//*******************************************************
//  * Name    :CANMatrix_J300_VCU_ACU_20250813.dbc
//  * Author  :MatrixCreat @WangHu
//  * Function:****
//  * Version :V1.0.0
//  * Data    :2025.08.19 20:11:57
//*******************************************************

VERSION "WangHu V1.0"

NS_ :

BS_:

BU_: FSD VCU

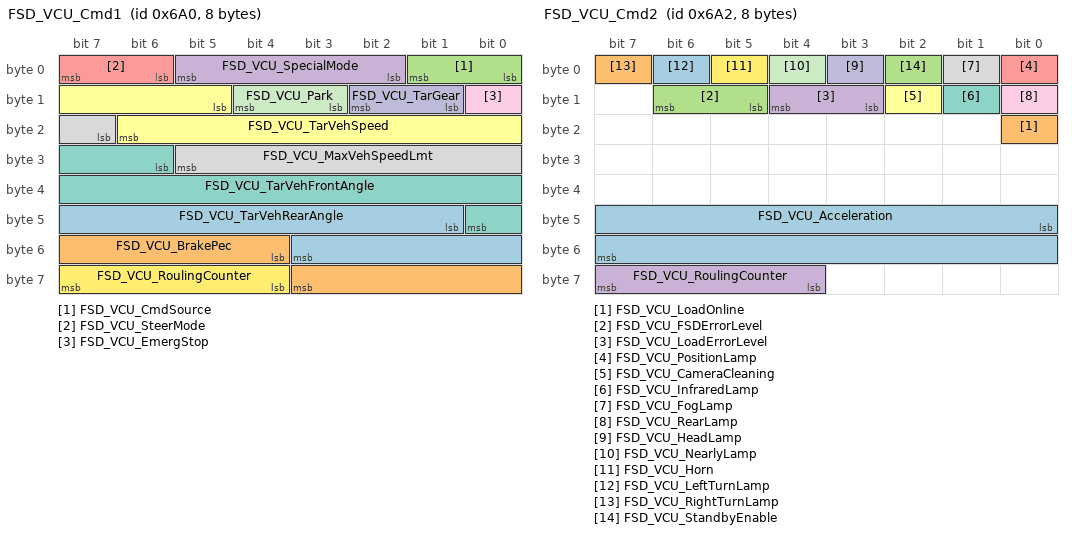
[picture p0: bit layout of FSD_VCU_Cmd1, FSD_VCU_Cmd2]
BO_ 1696 FSD_VCU_Cmd1: 8 FSD
 SG_ FSD_VCU_TarVehRearAngle : 41|11@1+ (1,-800) [-800|1247] "" Vector__XXX
 SG_ FSD_VCU_BrakePec : 52|8@1+ (1,0) [0|100] "" Vector__XXX
 SG_ FSD_VCU_CmdSource : 0|2@1+ (1,0) [0|0] "" Vector__XXX
 SG_ FSD_VCU_SpecialMode : 2|4@1+ (1,0) [0|15] "" Vector__XXX
 SG_ FSD_VCU_SteerMode : 6|2@1+ (1,0) [0|3] "" Vector__XXX
 SG_ FSD_VCU_TarVehSpeed : 13|10@1+ (0.1,0) [0|0] "" Vector__XXX
 SG_ FSD_VCU_TarVehFrontAngle : 30|11@1+ (1,-800) [-800|1247] "" Vector__XXX
 SG_ FSD_VCU_MaxVehSpeedLmt : 23|7@1+ (1,0) [0|127] "" Vector__XXX
 SG_ FSD_VCU_EmergStop : 8|1@1+ (1,0) [0|1] "" Vector__XXX
 SG_ FSD_VCU_TarGear : 9|2@1+ (1,0) [0|3] "" Vector__XXX
 SG_ FSD_VCU_Park : 11|2@1+ (1,0) [0|3] "" Vector__XXX
 SG_ FSD_VCU_RoulingCounter : 60|4@1+ (1,0) [0|15] "" Vector__XXX

BO_ 1698 FSD_VCU_Cmd2: 8 FSD
 SG_ FSD_VCU_Acceleration : 40|16@1+ (0.1,-5) [0|0] "" Vector__XXX
 SG_ FSD_VCU_LoadOnline : 16|1@1+ (1,0) [0|0] "" Vector__XXX
 SG_ FSD_VCU_FSDErrorLevel : 13|2@1+ (1,0) [0|0] "" Vector__XXX
 SG_ FSD_VCU_LoadErrorLevel : 11|2@1+ (1,0) [0|0] "" Vector__XXX
 SG_ FSD_VCU_PositionLamp : 0|1@1+ (1,0) [0|0] "" Vector__XXX
 SG_ FSD_VCU_CameraCleaning : 10|1@1+ (1,0) [0|0] "" Vector__XXX
 SG_ FSD_VCU_InfraredLamp : 9|1@1+ (1,0) [0|0] "" Vector__XXX
 SG_ FSD_VCU_FogLamp : 1|1@1+ (1,0) [0|0] "" Vector__XXX
 SG_ FSD_VCU_RearLamp : 8|1@1+ (1,0) [0|0] "" Vector__XXX
 SG_ FSD_VCU_HeadLamp : 3|1@1+ (1,0) [0|1] "" Vector__XXX
 SG_ FSD_VCU_NearlyLamp : 4|1@1+ (1,0) [0|1] "" Vector__XXX
 SG_ FSD_VCU_Horn : 5|1@1+ (1,0) [0|1] "" Vector__XXX
 SG_ FSD_VCU_LeftTurnLamp : 6|1@1+ (1,0) [0|1] "" Vector__XXX
 SG_ FSD_VCU_RightTurnLamp : 7|1@1+ (1,0) [0|1] "" Vector__XXX
 SG_ FSD_VCU_StandbyEnable : 2|1@1+ (1,0) [0|1] "" Vector__XXX
 SG_ FSD_VCU_RoulingCounter : 60|4@1+ (1,0) [0|15] "" Vector__XXX

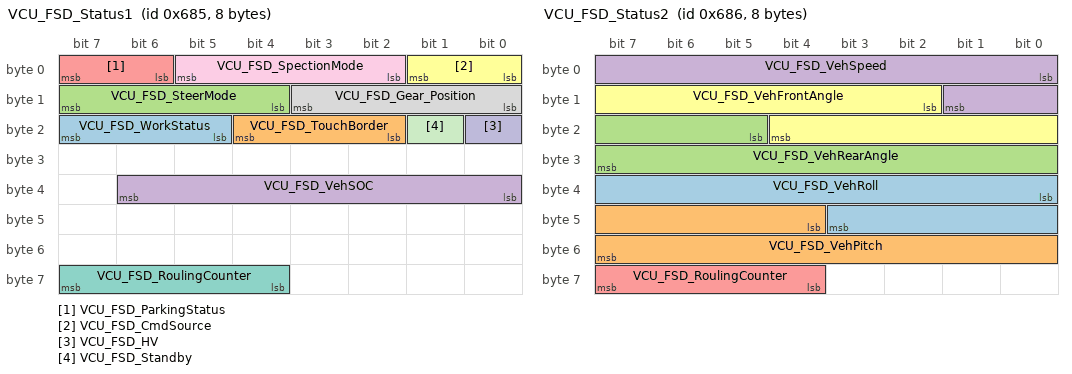
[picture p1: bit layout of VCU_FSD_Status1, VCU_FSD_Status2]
BO_ 1669 VCU_FSD_Status1: 8 VCU
 SG_ VCU_FSD_WorkStatus : 21|3@1+ (1,0) [0|0] "" Vector__XXX
 SG_ VCU_FSD_TouchBorder : 18|3@1+ (1,0) [0|0] "" Vector__XXX
 SG_ VCU_FSD_SteerMode : 12|4@1+ (1,0) [0|0] "" Vector__XXX
 SG_ VCU_FSD_VehSOC : 32|7@1+ (1,0) [0|127] "" Vector__XXX
 SG_ VCU_FSD_ParkingStatus : 6|2@1+ (1,0) [0|2] "" Vector__XXX
 SG_ VCU_FSD_CmdSource : 0|2@1+ (1,0) [0|3] "" Vector__XXX
 SG_ VCU_FSD_RoulingCounter : 60|4@1+ (1,0) [0|15] "" Vector__XXX
 SG_ VCU_FSD_Gear_Position : 8|4@1+ (1,0) [0|6] "" Vector__XXX
 SG_ VCU_FSD_SpectionMode : 2|4@1+ (1,0) [0|15] "" Vector__XXX
 SG_ VCU_FSD_HV : 16|1@1+ (1,0) [0|1] "" Vector__XXX
 SG_ VCU_FSD_Standby : 17|1@1+ (1,0) [0|1] "" Vector__XXX

BO_ 1670 VCU_FSD_Status2: 8 VCU
 SG_ VCU_FSD_VehRoll : 32|12@1+ (0.1,-180) [0|0] "" Vector__XXX
 SG_ VCU_FSD_VehPitch : 44|12@1+ (0.1,-180) [0|0] "" Vector__XXX
 SG_ VCU_FSD_VehRearAngle : 21|11@1+ (1,-800) [-800|1247] "" Vector__XXX
 SG_ VCU_FSD_VehSpeed : 0|10@1+ (0.1,0) [0|102.3] "" Vector__XXX
 SG_ VCU_FSD_RoulingCounter : 60|4@1+ (1,0) [0|15] "" Vector__XXX
 SG_ VCU_FSD_VehFrontAngle : 10|11@1+ (1,-800) [-800|1247] "" Vector__XXX

BO_ 1665 VCU_ErrorMsg1: 8 VCU
 SG_ VCU_DC24ErrorLevel : 34|2@1+ (1,0) [0|3] "" Vector__XXX
 SG_ VCU_LowVoltageBoxErrorLevel : 36|2@1+ (1,0) [0|3] "" Vector__XXX
 SG_ VCU_IMUErrorLevel : 38|2@1+ (1,0) [0|3] "" Vector__XXX
 SG_ VCU_CANbusError : 42|2@1+ (1,0) [0|3] "" Vector__XXX
 SG_ VCU_VehicleErrorLevel : 0|2@1+ (1,0) [0|0] "" Vector__XXX
 SG_ VCU_FrontMotorErrorLevel : 14|2@1+ (1,0) [0|3] "" Vector__XXX
 SG_ VCU_RearMotorErrorLevel : 16|2@1+ (1,0) [0|3] "" Vector__XXX
 SG_ VCU_RightBatteryErrorLevel : 20|2@1+ (1,0) [0|3] "" Vector__XXX
 SG_ VCU_DC12_1200wErrorLevel : 32|2@1+ (1,0) [0|3] "" Vector__XXX
 SG_ VCU_RightPowerErrorLevel : 12|2@1+ (1,0) [0|0] "" Vector__XXX
 SG_ VCU_LeftPowerErrorLevel : 10|2@1+ (1,0) [0|0] "" Vector__XXX
 SG_ VCU_FSDErrorLevel : 8|2@1+ (1,0) [0|0] "" Vector__XXX
 SG_ VCU_FrontAxleErrorLevel : 2|2@1+ (1,0) [0|0] "" Vector__XXX
 SG_ VCU_ChassisControlBoxLevel : 6|2@1+ (1,0) [0|0] "" Vector__XXX
 SG_ VCU_RearAxleErrorLevel : 4|2@1+ (1,0) [0|0] "" Vector__XXX
 SG_ VCU_LeftBatteryLevel : 18|2@1+ (1,0) [0|3] "" Vector__XXX
 SG_ VCU_DC12_600wLevel : 30|2@1+ (1,0) [0|3] "" Vector__XXX
 SG_ VCU_FrontEPSLevel : 26|2@1+ (1,0) [0|3] "" Vector__XXX
 SG_ VCU_RearEPSLevel : 28|2@1+ (1,0) [0|3] "" Vector__XXX
 SG_ VCU_FrontBrakeLevel : 22|2@1+ (1,0) [0|3] "" Vector__XXX
 SG_ VCU_RearBrakeLevel : 24|2@1+ (1,0) [0|3] "" Vector__XXX
 SG_ VCU_LoadErrorLevel : 40|2@1+ (1,0) [0|3] "" Vector__XXX
 SG_ VCU_RemoteErrorLevel : 44|2@1+ (1,0) [0|3] "" Vector__XXX

BO_ 1666 VCU_ErrorMsg2: 8 VCU
 SG_ VCU_DC24Online : 12|1@1+ (1,0) [0|0] "" Vector__XXX
 SG_ VCU_LowVoltageBoxOnline : 14|1@1+ (1,0) [0|0] "" Vector__XXX
 SG_ VCU_IMUOnline : 13|1@1+ (1,0) [0|0] "" Vector__XXX
 SG_ VCU_LoadOnline : 15|1@1+ (1,0) [0|0] "" Vector__XXX
 SG_ VCU_OnlineRoulingCounter : 60|4@1+ (1,0) [0|0] "" Vector__XXX
 SG_ VCU_ErrorCode : 40|16@1+ (1,0) [0|65535] "" Vector__XXX
 SG_ VCU_ShortRangRemote_online : 0|1@1+ (1,0) [0|1] "" Vector__XXX
 SG_ VCU_FrontMotor_online : 6|1@1+ (1,0) [0|1] "" Vector__XXX
 SG_ VCU_FrontEPS_online : 8|1@1+ (1,0) [0|1] "" Vector__XXX
 SG_ VCU_FrontBrake_online : 4|1@1+ (1,0) [0|1] "" Vector__XXX
 SG_ VCU_LeftBattery_online : 2|1@1+ (1,0) [0|1] "" Vector__XXX
 SG_ VCU_DC12_600w_online : 11|1@1+ (1,0) [0|1] "" Vector__XXX
 SG_ VCU_DC12_1200w_online : 10|1@1+ (1,0) [0|1] "" Vector__XXX
 SG_ VCU_RearMotor_online : 7|1@1+ (1,0) [0|1] "" Vector__XXX
 SG_ VCU_RearEPS_online : 9|1@1+ (1,0) [0|1] "" Vector__XXX
 SG_ VCU_RearBrake_online : 5|1@1+ (1,0) [0|1] "" Vector__XXX
 SG_ VCU_RightBattery_online : 3|1@1+ (1,0) [0|1] "" Vector__XXX
 SG_ VCU_FSD_online : 1|1@1+ (1,0) [0|1] "" Vector__XXX

CM_ SG_ 1696 FSD_VCU_TarVehRearAngle "Rear_axle_virtual_steering_wheel_angle";
CM_ SG_ 1696 FSD_VCU_BrakePec "Brake_opening_degree";
CM_ SG_ 1696 FSD_VCU_CmdSource "CmdSource";
CM_ SG_ 1696 FSD_VCU_SpecialMode "Special_Mode";
CM_ SG_ 1696 FSD_VCU_SteerMode "steering_mode";
CM_ SG_ 1696 FSD_VCU_TarVehSpeed "Target_speed";
CM_ SG_ 1696 FSD_VCU_TarVehFrontAngle "Front_axle_virtual_steering_wheel_angle";
CM_ SG_ 1696 FSD_VCU_MaxVehSpeedLmt "Maximum_speed_limit";
CM_ SG_ 1696 FSD_VCU_EmergStop "Emergency_stop";
CM_ SG_ 1696 FSD_VCU_TarGear "Target_gear";
CM_ SG_ 1696 FSD_VCU_Park "parking";
CM_ SG_ 1696 FSD_VCU_RoulingCounter "Life_signals";
CM_ SG_ 1698 FSD_VCU_Acceleration "Reserved_acceleration_control";
CM_ SG_ 1698 FSD_VCU_LoadOnline "Load_online_status";
CM_ SG_ 1698 FSD_VCU_FSDErrorLevel "FSD_fault_level";
CM_ SG_ 1698 FSD_VCU_LoadErrorLevel "Load_fault_level";
CM_ SG_ 1698 FSD_VCU_PositionLamp "position_light";
CM_ SG_ 1698 FSD_VCU_CameraCleaning "Camera_cleaning";
CM_ SG_ 1698 FSD_VCU_InfraredLamp "infrared_lamp";
CM_ SG_ 1698 FSD_VCU_FogLamp "fog_light";
CM_ SG_ 1698 FSD_VCU_RearLamp "reversing_light";
CM_ SG_ 1698 FSD_VCU_HeadLamp "high_beam";
CM_ SG_ 1698 FSD_VCU_NearlyLamp "low_beam";
CM_ SG_ 1698 FSD_VCU_Horn "horn";
CM_ SG_ 1698 FSD_VCU_LeftTurnLamp "Left_Turn_lamp";
CM_ SG_ 1698 FSD_VCU_RightTurnLamp "Right_turn_lamp";
CM_ SG_ 1698 FSD_VCU_StandbyEnable "Standby_Enable";
CM_ SG_ 1698 FSD_VCU_RoulingCounter "Life_signals";
CM_ SG_ 1669 VCU_FSD_WorkStatus "work_status";
CM_ SG_ 1669 VCU_FSD_TouchBorder "Safe_edge_contact_state";
CM_ SG_ 1669 VCU_FSD_SteerMode "steering_mode";
CM_ SG_ 1669 VCU_FSD_VehSOC "Vehicle_power_consumption";
CM_ SG_ 1669 VCU_FSD_ParkingStatus "Parking_brake_status";
CM_ SG_ 1669 VCU_FSD_CmdSource "Current_control_source";
CM_ SG_ 1669 VCU_FSD_RoulingCounter "Life_signals";
CM_ SG_ 1669 VCU_FSD_Gear_Position "gear";
CM_ SG_ 1669 VCU_FSD_SpectionMode "Special_mode_feedback";
CM_ SG_ 1669 VCU_FSD_HV "High_voltage_status_feedback";
CM_ SG_ 1669 VCU_FSD_Standby "Standby_state_feedback";
CM_ SG_ 1670 VCU_FSD_VehRoll "Vehicle_roll_angle";
CM_ SG_ 1670 VCU_FSD_VehPitch "Vehicle_pitch_angle";
CM_ SG_ 1670 VCU_FSD_VehRearAngle "Current_rear_axle_virtual_steering_wheel_angle";
CM_ SG_ 1670 VCU_FSD_VehSpeed "Current_vehicle_speed";
CM_ SG_ 1670 VCU_FSD_RoulingCounter "Life_signals";
CM_ SG_ 1670 VCU_FSD_VehFrontAngle "Current_virtual_steering_wheel_angle_of_front_axle";
CM_ SG_ 1665 VCU_DC24ErrorLevel "DCDC_24V_fault_level";
CM_ SG_ 1665 VCU_LowVoltageBoxErrorLevel "Fault_level_of_low-voltage_distribution_box";
CM_ SG_ 1665 VCU_IMUErrorLevel "IMU_fault_level";
CM_ SG_ 1665 VCU_CANbusError "CAN_bus_fault";
CM_ SG_ 1665 VCU_VehicleErrorLevel "Vehicle_fault_level";
CM_ SG_ 1665 VCU_FrontMotorErrorLevel "Fault_level_of_front_drive_motor";
CM_ SG_ 1665 VCU_RearMotorErrorLevel "Fault_level_of_rear_drive_motor";
CM_ SG_ 1665 VCU_RightBatteryErrorLevel "Right_battery_pack_fault_level";
CM_ SG_ 1665 VCU_DC12_1200wErrorLevel "1200w_DCDC_12V_fault_level";
CM_ SG_ 1665 VCU_RightPowerErrorLevel "Fault_level_of_right_battery_box";
CM_ SG_ 1665 VCU_LeftPowerErrorLevel "Left_battery_box_fault_level";
CM_ SG_ 1665 VCU_FSDErrorLevel "FSD_module_fault_level";
CM_ SG_ 1665 VCU_FrontAxleErrorLevel "Front_axle_fault_level";
CM_ SG_ 1665 VCU_ChassisControlBoxLevel "Fault_level_of_chassis_control_box";
CM_ SG_ 1665 VCU_RearAxleErrorLevel "Rear_axle_fault_level";
CM_ SG_ 1665 VCU_LeftBatteryLevel "Left_battery_pack_fault_level";
CM_ SG_ 1665 VCU_DC12_600wLevel "600W_DCDC_12V_fault_level";
CM_ SG_ 1665 VCU_FrontEPSLevel "Front_EPS_fault_level";
CM_ SG_ 1665 VCU_RearEPSLevel "rear_EPS_fault_level";
CM_ SG_ 1665 VCU_FrontBrakeLevel "Front_brake_fault_level";
CM_ SG_ 1665 VCU_RearBrakeLevel "Rear_brake_fault_level";
CM_ SG_ 1665 VCU_LoadErrorLevel "Load_fault_level";
CM_ SG_ 1665 VCU_RemoteErrorLevel "Remote_control_fault_level";
CM_ SG_ 1666 VCU_DC24Online "DC24V_online_status";
CM_ SG_ 1666 VCU_LowVoltageBoxOnline "Low_voltage_distribution_box_online_status";
CM_ SG_ 1666 VCU_IMUOnline "IMU_online_status";
CM_ SG_ 1666 VCU_LoadOnline "Load_online_status";
CM_ SG_ 1666 VCU_OnlineRoulingCounter "Life_signals";
CM_ SG_ 1666 VCU_ErrorCode "Vehicle_fault_code";
CM_ SG_ 1666 VCU_ShortRangRemote_online "Close_range_remote_control_online_status";
CM_ SG_ 1666 VCU_FrontMotor_online "Front_drive_motor_online_status";
CM_ SG_ 1666 VCU_FrontEPS_online "Front_EPS_online_status";
CM_ SG_ 1666 VCU_FrontBrake_online "Front_brake_online_status";
CM_ SG_ 1666 VCU_LeftBattery_online "Left_battery_pack_online_status";
CM_ SG_ 1666 VCU_DC12_600w_online "600W_DCDC_12V_online_status";
CM_ SG_ 1666 VCU_DC12_1200w_online "1200W_DCDC_12V_online_status";
CM_ SG_ 1666 VCU_RearMotor_online "Rear_drive_motor_online_status";
CM_ SG_ 1666 VCU_RearEPS_online "Rear_EPS_online_status";
CM_ SG_ 1666 VCU_RearBrake_online "Rear_brake_online_status";
CM_ SG_ 1666 VCU_RightBattery_online "Right_battery_pack_online_status";
CM_ SG_ 1666 VCU_FSD_online "FSD_online_status";

BA_DEF_ SG_  "GenSigStartValue" FLOAT 0 1215752192;
BA_DEF_ SG_  "GenSigMaxValue" INT 0 2147483647;
BA_DEF_ SG_  "GenSigSendType" ENUM "FixedPeriodic", "Cyclic";
BA_DEF_ SG_  "GenSigEnvVarType" ENUM  "int","float","undef";
BA_DEF_ BO_  "GenMsgDelayTime" INT 0 0;
BA_DEF_ BO_  "GenMsgNrOfRepetition" INT 0 0;
BA_DEF_ BO_  "GenMsgCycleTime" INT 0 65535;
BA_DEF_ BO_  "GenMsgSendType" ENUM "FixedPeriodic", "Cyclic";
BA_DEF_  "BusType" STRING ;
BA_DEF_  "GenEnvVarPrefix" STRING ;
BA_DEF_  "GenEnvVarEndingSnd" STRING ;
BA_DEF_  "GenEnvVarEndingDsp" STRING ;
BA_DEF_  "DBName" STRING ;
BA_DEF_DEF_  "GenMsgDelayTime" 0;
BA_DEF_DEF_  "GenMsgNrOfRepetition" 0;
BA_DEF_DEF_  "GenSigStartValue" 0;
BA_DEF_DEF_  "GenSigMaxValue" 0;
BA_DEF_DEF_  "GenSigSendType" "FixedPeriodic";
BA_DEF_DEF_  "GenSigEnvVarType" "undef";
BA_DEF_DEF_  "GenMsgCycleTime" 0;
BA_DEF_DEF_  "GenMsgSendType" "FixedPeriodic";
BA_DEF_DEF_  "BusType" "CAN";
BA_DEF_DEF_  "GenEnvVarPrefix" "PE";
BA_DEF_DEF_  "GenEnvVarEndingSnd" "_Ps";
BA_DEF_DEF_  "GenEnvVarEndingDsp" "_Pd";
BA_DEF_DEF_  "DBName" "";

BA_ "DBName" "CanMatrix";
BA_ "GenMsgCycleTime" BO_ 1696 20;
BA_ "GenMsgNrOfRepetition" BO_ 1696 1;
BA_ "GenMsgDelayTime" BO_ 1696 1;
BA_ "GenSigMaxValue" SG_ 1696 FSD_VCU_TarVehRearAngle 4095;
BA_ "GenSigSendType" SG_ 1696 FSD_VCU_TarVehRearAngle 1;
BA_ "GenSigMaxValue" SG_ 1696 FSD_VCU_BrakePec 255;
BA_ "GenSigSendType" SG_ 1696 FSD_VCU_BrakePec 1;
BA_ "GenSigSendType" SG_ 1696 FSD_VCU_CmdSource 1;
BA_ "GenSigMaxValue" SG_ 1696 FSD_VCU_SpecialMode 15;
BA_ "GenSigSendType" SG_ 1696 FSD_VCU_SpecialMode 1;
BA_ "GenSigMaxValue" SG_ 1696 FSD_VCU_SteerMode 15;
BA_ "GenSigSendType" SG_ 1696 FSD_VCU_SteerMode 1;
BA_ "GenSigMaxValue" SG_ 1696 FSD_VCU_TarVehSpeed 4095;
BA_ "GenSigSendType" SG_ 1696 FSD_VCU_TarVehSpeed 1;
BA_ "GenSigMaxValue" SG_ 1696 FSD_VCU_TarVehFrontAngle 4095;
BA_ "GenSigSendType" SG_ 1696 FSD_VCU_TarVehFrontAngle 1;
BA_ "GenSigMaxValue" SG_ 1696 FSD_VCU_MaxVehSpeedLmt 255;
BA_ "GenSigSendType" SG_ 1696 FSD_VCU_MaxVehSpeedLmt 1;
BA_ "GenSigMaxValue" SG_ 1696 FSD_VCU_EmergStop 1;
BA_ "GenSigSendType" SG_ 1696 FSD_VCU_EmergStop 1;
BA_ "GenSigMaxValue" SG_ 1696 FSD_VCU_TarGear 3;
BA_ "GenSigSendType" SG_ 1696 FSD_VCU_TarGear 1;
BA_ "GenSigMaxValue" SG_ 1696 FSD_VCU_Park 3;
BA_ "GenSigSendType" SG_ 1696 FSD_VCU_Park 1;
BA_ "GenSigMaxValue" SG_ 1696 FSD_VCU_RoulingCounter 15;
BA_ "GenSigSendType" SG_ 1696 FSD_VCU_RoulingCounter 1;
BA_ "GenMsgCycleTime" BO_ 1698 100;
BA_ "GenMsgNrOfRepetition" BO_ 1698 1;
BA_ "GenMsgDelayTime" BO_ 1698 1;
BA_ "GenSigStartValue" SG_ 1698 FSD_VCU_Acceleration 50;
BA_ "GenSigSendType" SG_ 1698 FSD_VCU_Acceleration 1;
BA_ "GenSigSendType" SG_ 1698 FSD_VCU_LoadOnline 1;
BA_ "GenSigSendType" SG_ 1698 FSD_VCU_FSDErrorLevel 1;
BA_ "GenSigSendType" SG_ 1698 FSD_VCU_LoadErrorLevel 1;
BA_ "GenSigSendType" SG_ 1698 FSD_VCU_PositionLamp 1;
BA_ "GenSigSendType" SG_ 1698 FSD_VCU_CameraCleaning 1;
BA_ "GenSigSendType" SG_ 1698 FSD_VCU_InfraredLamp 1;
BA_ "GenSigSendType" SG_ 1698 FSD_VCU_FogLamp 1;
BA_ "GenSigSendType" SG_ 1698 FSD_VCU_RearLamp 1;
BA_ "GenSigMaxValue" SG_ 1698 FSD_VCU_HeadLamp 1;
BA_ "GenSigSendType" SG_ 1698 FSD_VCU_HeadLamp 1;
BA_ "GenSigMaxValue" SG_ 1698 FSD_VCU_NearlyLamp 1;
BA_ "GenSigSendType" SG_ 1698 FSD_VCU_NearlyLamp 1;
BA_ "GenSigMaxValue" SG_ 1698 FSD_VCU_Horn 1;
BA_ "GenSigSendType" SG_ 1698 FSD_VCU_Horn 1;
BA_ "GenSigMaxValue" SG_ 1698 FSD_VCU_LeftTurnLamp 1;
BA_ "GenSigSendType" SG_ 1698 FSD_VCU_LeftTurnLamp 1;
BA_ "GenSigMaxValue" SG_ 1698 FSD_VCU_RightTurnLamp 1;
BA_ "GenSigSendType" SG_ 1698 FSD_VCU_RightTurnLamp 1;
BA_ "GenSigMaxValue" SG_ 1698 FSD_VCU_StandbyEnable 1;
BA_ "GenSigSendType" SG_ 1698 FSD_VCU_StandbyEnable 1;
BA_ "GenSigMaxValue" SG_ 1698 FSD_VCU_RoulingCounter 15;
BA_ "GenSigSendType" SG_ 1698 FSD_VCU_RoulingCounter 1;
BA_ "GenMsgCycleTime" BO_ 1669 20;
BA_ "GenMsgNrOfRepetition" BO_ 1669 1;
BA_ "GenMsgDelayTime" BO_ 1669 1;
BA_ "GenSigSendType" SG_ 1669 VCU_FSD_WorkStatus 1;
BA_ "GenSigSendType" SG_ 1669 VCU_FSD_TouchBorder 1;
BA_ "GenSigSendType" SG_ 1669 VCU_FSD_SteerMode 1;
BA_ "GenSigMaxValue" SG_ 1669 VCU_FSD_VehSOC 255;
BA_ "GenSigSendType" SG_ 1669 VCU_FSD_VehSOC 1;
BA_ "GenSigMaxValue" SG_ 1669 VCU_FSD_ParkingStatus 3;
BA_ "GenSigSendType" SG_ 1669 VCU_FSD_ParkingStatus 1;
BA_ "GenSigMaxValue" SG_ 1669 VCU_FSD_CmdSource 1;
BA_ "GenSigSendType" SG_ 1669 VCU_FSD_CmdSource 1;
BA_ "GenSigMaxValue" SG_ 1669 VCU_FSD_RoulingCounter 15;
BA_ "GenSigSendType" SG_ 1669 VCU_FSD_RoulingCounter 1;
BA_ "GenSigMaxValue" SG_ 1669 VCU_FSD_Gear_Position 15;
BA_ "GenSigSendType" SG_ 1669 VCU_FSD_Gear_Position 1;
BA_ "GenSigMaxValue" SG_ 1669 VCU_FSD_SpectionMode 15;
BA_ "GenSigSendType" SG_ 1669 VCU_FSD_SpectionMode 1;
BA_ "GenSigMaxValue" SG_ 1669 VCU_FSD_HV 1;
BA_ "GenSigSendType" SG_ 1669 VCU_FSD_HV 1;
BA_ "GenSigMaxValue" SG_ 1669 VCU_FSD_Standby 1;
BA_ "GenSigSendType" SG_ 1669 VCU_FSD_Standby 1;
BA_ "GenMsgCycleTime" BO_ 1670 20;
BA_ "GenMsgNrOfRepetition" BO_ 1670 1;
BA_ "GenMsgDelayTime" BO_ 1670 1;
BA_ "GenSigStartValue" SG_ 1670 VCU_FSD_VehRoll 1800;
BA_ "GenSigSendType" SG_ 1670 VCU_FSD_VehRoll 1;
BA_ "GenSigStartValue" SG_ 1670 VCU_FSD_VehPitch 1800;
BA_ "GenSigSendType" SG_ 1670 VCU_FSD_VehPitch 1;
BA_ "GenSigSendType" SG_ 1670 VCU_FSD_VehRearAngle 1;
BA_ "GenSigMaxValue" SG_ 1670 VCU_FSD_VehSpeed 4095;
BA_ "GenSigSendType" SG_ 1670 VCU_FSD_VehSpeed 1;
BA_ "GenSigMaxValue" SG_ 1670 VCU_FSD_RoulingCounter 15;
BA_ "GenSigSendType" SG_ 1670 VCU_FSD_RoulingCounter 1;
BA_ "GenSigSendType" SG_ 1670 VCU_FSD_VehFrontAngle 1;
BA_ "GenMsgCycleTime" BO_ 1665 100;
BA_ "GenMsgNrOfRepetition" BO_ 1665 1;
BA_ "GenMsgDelayTime" BO_ 1665 1;
BA_ "GenMsgSendType" BO_ 1665 1;
BA_ "GenSigMaxValue" SG_ 1665 VCU_DC24ErrorLevel 15;
BA_ "GenSigSendType" SG_ 1665 VCU_DC24ErrorLevel 1;
BA_ "GenSigMaxValue" SG_ 1665 VCU_LowVoltageBoxErrorLevel 15;
BA_ "GenSigSendType" SG_ 1665 VCU_LowVoltageBoxErrorLevel 1;
BA_ "GenSigMaxValue" SG_ 1665 VCU_IMUErrorLevel 15;
BA_ "GenSigSendType" SG_ 1665 VCU_IMUErrorLevel 1;
BA_ "GenSigMaxValue" SG_ 1665 VCU_CANbusError 15;
BA_ "GenSigSendType" SG_ 1665 VCU_CANbusError 1;
BA_ "GenSigSendType" SG_ 1665 VCU_VehicleErrorLevel 1;
BA_ "GenSigMaxValue" SG_ 1665 VCU_FrontMotorErrorLevel 15;
BA_ "GenSigSendType" SG_ 1665 VCU_FrontMotorErrorLevel 1;
BA_ "GenSigMaxValue" SG_ 1665 VCU_RearMotorErrorLevel 15;
BA_ "GenSigSendType" SG_ 1665 VCU_RearMotorErrorLevel 1;
BA_ "GenSigMaxValue" SG_ 1665 VCU_RightBatteryErrorLevel 15;
BA_ "GenSigSendType" SG_ 1665 VCU_RightBatteryErrorLevel 1;
BA_ "GenSigMaxValue" SG_ 1665 VCU_DC12_1200wErrorLevel 15;
BA_ "GenSigSendType" SG_ 1665 VCU_DC12_1200wErrorLevel 1;
BA_ "GenSigSendType" SG_ 1665 VCU_RightPowerErrorLevel 1;
BA_ "GenSigSendType" SG_ 1665 VCU_LeftPowerErrorLevel 1;
BA_ "GenSigSendType" SG_ 1665 VCU_FSDErrorLevel 1;
BA_ "GenSigSendType" SG_ 1665 VCU_FrontAxleErrorLevel 1;
BA_ "GenSigSendType" SG_ 1665 VCU_ChassisControlBoxLevel 1;
BA_ "GenSigSendType" SG_ 1665 VCU_RearAxleErrorLevel 1;
BA_ "GenSigMaxValue" SG_ 1665 VCU_LeftBatteryLevel 15;
BA_ "GenSigSendType" SG_ 1665 VCU_LeftBatteryLevel 1;
BA_ "GenSigMaxValue" SG_ 1665 VCU_DC12_600wLevel 15;
BA_ "GenSigSendType" SG_ 1665 VCU_DC12_600wLevel 1;
BA_ "GenSigMaxValue" SG_ 1665 VCU_FrontEPSLevel 15;
BA_ "GenSigSendType" SG_ 1665 VCU_FrontEPSLevel 1;
BA_ "GenSigMaxValue" SG_ 1665 VCU_RearEPSLevel 15;
BA_ "GenSigSendType" SG_ 1665 VCU_RearEPSLevel 1;
BA_ "GenSigMaxValue" SG_ 1665 VCU_FrontBrakeLevel 15;
BA_ "GenSigSendType" SG_ 1665 VCU_FrontBrakeLevel 1;
BA_ "GenSigMaxValue" SG_ 1665 VCU_RearBrakeLevel 15;
BA_ "GenSigSendType" SG_ 1665 VCU_RearBrakeLevel 1;
BA_ "GenSigMaxValue" SG_ 1665 VCU_LoadErrorLevel 15;
BA_ "GenSigSendType" SG_ 1665 VCU_LoadErrorLevel 1;
BA_ "GenSigMaxValue" SG_ 1665 VCU_RemoteErrorLevel 15;
BA_ "GenSigSendType" SG_ 1665 VCU_RemoteErrorLevel 1;
BA_ "GenMsgCycleTime" BO_ 1666 100;
BA_ "GenMsgNrOfRepetition" BO_ 1666 1;
BA_ "GenMsgDelayTime" BO_ 1666 1;
BA_ "GenMsgSendType" BO_ 1666 1;
BA_ "GenSigSendType" SG_ 1666 VCU_DC24Online 1;
BA_ "GenSigSendType" SG_ 1666 VCU_LowVoltageBoxOnline 1;
BA_ "GenSigSendType" SG_ 1666 VCU_IMUOnline 1;
BA_ "GenSigSendType" SG_ 1666 VCU_LoadOnline 1;
BA_ "GenSigSendType" SG_ 1666 VCU_OnlineRoulingCounter 1;
BA_ "GenSigMaxValue" SG_ 1666 VCU_ErrorCode 65535;
BA_ "GenSigSendType" SG_ 1666 VCU_ErrorCode 1;
BA_ "GenSigMaxValue" SG_ 1666 VCU_ShortRangRemote_online 1;
BA_ "GenSigSendType" SG_ 1666 VCU_ShortRangRemote_online 1;
BA_ "GenSigMaxValue" SG_ 1666 VCU_FrontMotor_online 1;
BA_ "GenSigSendType" SG_ 1666 VCU_FrontMotor_online 1;
BA_ "GenSigMaxValue" SG_ 1666 VCU_FrontEPS_online 1;
BA_ "GenSigSendType" SG_ 1666 VCU_FrontEPS_online 1;
BA_ "GenSigMaxValue" SG_ 1666 VCU_FrontBrake_online 1;
BA_ "GenSigSendType" SG_ 1666 VCU_FrontBrake_online 1;
BA_ "GenSigMaxValue" SG_ 1666 VCU_LeftBattery_online 1;
BA_ "GenSigSendType" SG_ 1666 VCU_LeftBattery_online 1;
BA_ "GenSigMaxValue" SG_ 1666 VCU_DC12_600w_online 1;
BA_ "GenSigSendType" SG_ 1666 VCU_DC12_600w_online 1;
BA_ "GenSigMaxValue" SG_ 1666 VCU_DC12_1200w_online 1;
BA_ "GenSigSendType" SG_ 1666 VCU_DC12_1200w_online 1;
BA_ "GenSigMaxValue" SG_ 1666 VCU_RearMotor_online 1;
BA_ "GenSigSendType" SG_ 1666 VCU_RearMotor_online 1;
BA_ "GenSigMaxValue" SG_ 1666 VCU_RearEPS_online 1;
BA_ "GenSigSendType" SG_ 1666 VCU_RearEPS_online 1;
BA_ "GenSigMaxValue" SG_ 1666 VCU_RearBrake_online 1;
BA_ "GenSigSendType" SG_ 1666 VCU_RearBrake_online 1;
BA_ "GenSigMaxValue" SG_ 1666 VCU_RightBattery_online 1;
BA_ "GenSigSendType" SG_ 1666 VCU_RightBattery_online 1;
BA_ "GenSigMaxValue" SG_ 1666 VCU_FSD_online 1;
BA_ "GenSigSendType" SG_ 1666 VCU_FSD_online 1;

VAL_ 1696 FSD_VCU_CmdSource 0 " Not selected " 1 "FSD " 2 " Close range remote control";
VAL_ 1696 FSD_VCU_SpecialMode 0 " Bench mode " 1 " Economic Model " 2 " Standard Mode " 3 " Sand Mode " 4 " Ramp mode " 5 " Mud mode";
VAL_ 1696 FSD_VCU_SteerMode 0 " Front axle steering " 1 " Full bridge steering " 2 " Rear axle steering";
VAL_ 1696 FSD_VCU_EmergStop 0 " No emergency stop " 1 " Emergency stop";
VAL_ 1696 FSD_VCU_TarGear 0 "N" 1 "D" 2 "R";
VAL_ 1696 FSD_VCU_Park 0 " Parking " 1 " Release parking";
VAL_ 1698 FSD_VCU_LoadOnline 0 "offline" 1 "online";
VAL_ 1698 FSD_VCU_FSDErrorLevel 0 "No fault" 1 "Minor fault" 2 "General fault" 3 "Serious fault";
VAL_ 1698 FSD_VCU_LoadErrorLevel 0 "No fault" 1 "Minor fault" 2 "General fault" 3 "Serious fault";
VAL_ 1698 FSD_VCU_PositionLamp 0 "disable" 1 "enable";
VAL_ 1698 FSD_VCU_CameraCleaning 0 "disable" 1 "enable";
VAL_ 1698 FSD_VCU_InfraredLamp 0 "disable" 1 "enable";
VAL_ 1698 FSD_VCU_FogLamp 0 "disable" 1 "enable";
VAL_ 1698 FSD_VCU_RearLamp 0 "disable" 1 "enable";
VAL_ 1698 FSD_VCU_HeadLamp 0 "disable" 1 "enable";
VAL_ 1698 FSD_VCU_NearlyLamp 0 "disable" 1 "enable";
VAL_ 1698 FSD_VCU_Horn 0 "disable" 1 "enable";
VAL_ 1698 FSD_VCU_LeftTurnLamp 0 "disable" 1 "enable";
VAL_ 1698 FSD_VCU_RightTurnLamp 0 "disable" 1 "enable";
VAL_ 1698 FSD_VCU_StandbyEnable 0 "disable" 1 "enable";
VAL_ 1669 VCU_FSD_WorkStatus 0 " Normal operation " 1 " limping " 2 " Fault parking";
VAL_ 1669 VCU_FSD_TouchBorder 0 " No contact " 1 " Contact";
VAL_ 1669 VCU_FSD_SteerMode 0 " Front axle steering " 1 " Full bridge steering " 2 " Rear axle steering";
VAL_ 1669 VCU_FSD_ParkingStatus 0 " Not parked " 1 " Parking";
VAL_ 1669 VCU_FSD_CmdSource 0 " Not selected " 1 "FSD " 2 " Close range remote control";
VAL_ 1669 VCU_FSD_Gear_Position 0 "N" 1 "D" 2 "R";
VAL_ 1669 VCU_FSD_SpectionMode 0 " Bench mode " 1 " Economic Model " 2 " Standard Mode " 3 " Sand Mode " 4 " Ramp mode " 5 " Mud mode";
VAL_ 1669 VCU_FSD_HV 0 " High voltage not applied " 1 " High Voltage";
VAL_ 1669 VCU_FSD_Standby 0 " Standby " 1 " Not in standby mode";
VAL_ 1665 VCU_DC24ErrorLevel 0 "No fault" 1 "Minor fault" 2 "General fault" 3 "Serious fault";
VAL_ 1665 VCU_LowVoltageBoxErrorLevel 0 "No fault" 1 "Minor fault" 2 "General fault" 3 "Serious fault";
VAL_ 1665 VCU_IMUErrorLevel 0 "No fault" 1 "Minor fault" 2 "General fault" 3 "Serious fault";
VAL_ 1665 VCU_CANbusError 0 "FCANBUS fault" 1 "RCANBUS fault" 2 "FRCANBUS fault";
VAL_ 1665 VCU_VehicleErrorLevel 0 "No fault" 1 "Minor fault" 2 "General fault" 3 "Serious fault";
VAL_ 1665 VCU_FrontMotorErrorLevel 0 "No fault" 1 "Minor fault" 2 "General fault" 3 "Serious fault";
VAL_ 1665 VCU_RearMotorErrorLevel 0 "No fault" 1 "Minor fault" 2 "General fault" 3 "Serious fault";
VAL_ 1665 VCU_RightBatteryErrorLevel 0 "No fault" 1 "Minor fault" 2 "General fault" 3 "Serious fault";
VAL_ 1665 VCU_DC12_1200wErrorLevel 0 "No fault" 1 "Minor fault" 2 "General fault" 3 "Serious fault";
VAL_ 1665 VCU_RightPowerErrorLevel 0 "No fault" 1 "Minor fault" 2 "General fault" 3 "Serious fault";
VAL_ 1665 VCU_LeftPowerErrorLevel 0 "No fault" 1 "Minor fault" 2 "General fault" 3 "Serious fault";
VAL_ 1665 VCU_FSDErrorLevel 0 "FCANBUS fault" 1 "RCANBUS fault" 2 "FRCANBUS fault";
VAL_ 1665 VCU_FrontAxleErrorLevel 0 "No fault" 1 "Minor fault" 2 "General fault" 3 "Serious fault";
VAL_ 1665 VCU_ChassisControlBoxLevel 0 "No fault" 1 "Minor fault" 2 "General fault" 3 "Serious fault";
VAL_ 1665 VCU_RearAxleErrorLevel 0 "No fault" 1 "Minor fault" 2 "General fault" 3 "Serious fault";
VAL_ 1665 VCU_LeftBatteryLevel 0 "No fault" 1 "Minor fault" 2 "General fault" 3 "Serious fault";
VAL_ 1665 VCU_DC12_600wLevel 0 "No fault" 1 "Minor fault" 2 "General fault" 3 "Serious fault";
VAL_ 1665 VCU_FrontEPSLevel 0 "No fault" 1 "Minor fault" 2 "General fault" 3 "Serious fault";
VAL_ 1665 VCU_RearEPSLevel 0 "No fault" 1 "Minor fault" 2 "General fault" 3 "Serious fault";
VAL_ 1665 VCU_FrontBrakeLevel 0 "No fault" 1 "Minor fault" 2 "General fault" 3 "Serious fault";
VAL_ 1665 VCU_RearBrakeLevel 0 "No fault" 1 "Minor fault" 2 "General fault" 3 "Serious fault";
VAL_ 1665 VCU_LoadErrorLevel 0 "No fault" 1 "Minor fault" 2 "General fault" 3 "Serious fault";
VAL_ 1665 VCU_RemoteErrorLevel 0 "No fault" 1 "Minor fault" 2 "General fault" 3 "Serious fault";
VAL_ 1666 VCU_DC24Online 0 "offline" 1 "online";
VAL_ 1666 VCU_LowVoltageBoxOnline 0 "offline" 1 "online";
VAL_ 1666 VCU_IMUOnline 0 "offline" 1 "online";
VAL_ 1666 VCU_LoadOnline 0 "offline" 1 "online";
VAL_ 1666 VCU_ErrorCode 0 "offline" 1 "online";
VAL_ 1666 VCU_ShortRangRemote_online 0 "offline" 1 "online";
VAL_ 1666 VCU_FrontMotor_online 0 "offline" 1 "online";
VAL_ 1666 VCU_FrontEPS_online 0 "offline" 1 "online";
VAL_ 1666 VCU_FrontBrake_online 0 "offline" 1 "online";
VAL_ 1666 VCU_LeftBattery_online 0 "offline" 1 "online";
VAL_ 1666 VCU_DC12_600w_online 0 "offline" 1 "online";
VAL_ 1666 VCU_DC12_1200w_online 0 "offline" 1 "online";
VAL_ 1666 VCU_RearMotor_online 0 "offline" 1 "online";
VAL_ 1666 VCU_RearEPS_online 0 "offline" 1 "online";
VAL_ 1666 VCU_RearBrake_online 0 "offline" 1 "online";
VAL_ 1666 VCU_RightBattery_online 0 "offline" 1 "online";
VAL_ 1666 VCU_FSD_online 0 "offline" 1 "online";
